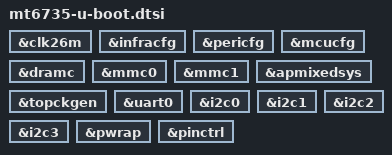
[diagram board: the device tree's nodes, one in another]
// SPDX-License-Identifier: GPL-2.0

#include "mt6735.dtsi"

&clk26m {
    bootph-all;
};

&infracfg {
    bootph-all;
};

&pericfg {
    bootph-all;
};

&mcucfg {
    bootph-all;
};

&dramc {
    bootph-all;
};

&mmc0 {
    bootph-all;
};

&mmc1 {
    bootph-all;
};

&apmixedsys {
    bootph-all;
};

&topckgen {
    bootph-all;
};

&uart0 {
    bootph-all;
};

&i2c0 {
    bootph-all;
};

&i2c1 {
    bootph-all;
};

&i2c2 {
    bootph-all;
};

&i2c3 {
    bootph-all;
};

&pwrap {
    bootph-all;
};

&pinctrl {
    bootph-all;
};

